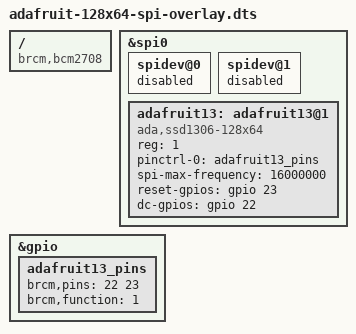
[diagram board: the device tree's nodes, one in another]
/*
 * Raspberry Pi Device Tree overlay for Adafruit
 * Monochrome 1.3" 128x64 OLED graphic display
 *
 */

/dts-v1/;
/plugin/;

/ {
	compatible = "brcm,bcm2708";
	
	fragment@0 {
		target = <&spi0>;
		__overlay__ {
			status = "okay";

			spidev@0{
				status = "disabled";
			};

			spidev@1{
				status = "disabled";
			};
		};
	};

	fragment@1 {
		target = <&gpio>;
		__overlay__ {
			adafruit13_pins: adafruit13_pins {
				brcm,pins = <22 23>;
				brcm,function = <1>; /* out */
			};
		};
	};

	fragment@2 {
		target = <&spi0>;
		__overlay__ {
			/* needed to avoid dtc warning */
			#address-cells = <1>;
			#size-cells = <0>;

			adafruit13: adafruit13@1{
				compatible = "ada,ssd1306-128x64";
				reg = <1>;
				pinctrl-names = "default";
				pinctrl-0 = <&adafruit13_pins>;

				spi-max-frequency = <16000000>;
				reset-gpios = <&gpio 23 0>;
				dc-gpios = <&gpio 22 0>;
			};
		};
	};

	__overrides__ {
		speed =   <&adafruit13>,"spi-max-frequency:0";
	};
};
